# MPS2_SSE_200 register map
Vendor: ARM Ltd.; Series: ARMv8-M Mainline; File version: 1.0
CPU: CM33 r0p0, little endian, MPU, no FPU, 4 interrupt priority bits, 8 SAU regions
Registers are 32-bit, read-write, reset 0x0 unless marked. A register's access mark holds for its fields unless they carry their own. Offsets are from the block's base; [hi:lo] are bit positions; {n}, {i} and the like mark numbered series.

## GPIO0 — General-purpose I/O 0
Base 0x40100000
Same registers: GPIO1 0x40101000, GPIO2 0x40102000, GPIO3 0x40103000, GPIO0_Secure 0x50100000, GPIO1_Secure 0x50101000, GPIO2_Secure 0x50102000, GPIO3_Secure 0x50103000
0x00 DATA
0x04 DATAOUT — Data Output Register
0x10 OUTENSET — Ouptut enable set Register
0x14 OUTENCLR — Ouptut enable clear Register
0x18 ALTFUNCSET — Alternate function set Register
0x1C ALTFUNCCLR — Alternate function clear Register
0x20 INTENSET — Interrupt enable set Register
0x24 INTENCLR — Interrupt enable clear Register
0x28 INTTYPESET — Interrupt type set Register
0x2C INTTYPECLR — Interrupt type clear Register
0x30 INTPOLSET — Polarity-level, edge interrupt configuration set Register
0x34 INTPOLCLR — Polarity-level, edge interrupt configuration clear Register
0x38 INTSTATUS ro — Interrupt Status Register
0x38 INTCLEAR wo write-1-clears (alternate view of INTSTATUS) — Interrupt CLEAR Register

## I2C0
Base 0x40207000
Same registers: I2C1 0x40208000, I2C2 0x4020C000, I2C3 0x4020D000, I2C0_Secure 0x50207000, I2C1_Secure 0x50208000, I2C2_Secure 0x5020C000, I2C3_Secure 0x5020D000
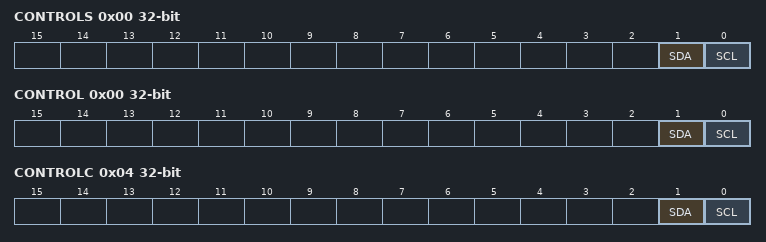
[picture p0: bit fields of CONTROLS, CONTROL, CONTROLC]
0x00 CONTROLS wo — Control Set
  [1] SDA — Serial data line
  [0] SCL — Serial clock line
0x00 CONTROL ro (alternate view of CONTROLS) — Control Status
  [1] SDA — Serial data line
  [0] SCL — Serial clock line
0x04 CONTROLC — Control Clear
  [1] SDA — Serial data line
  [0] SCL — Serial clock line

## WATCHDOG — Non-secure Watchdog Timer
Base 0x40081000
Same registers: S32KWATCHDOG_Secure 0x5002E000, WATCHDOG_Secure 0x50081000
0x00 WDOGLOAD reset 0xFFFFFFFF — Watchdog Load Register
0x04 WDOGVALUE ro reset 0xFFFFFFFF — Watchdog Value Register
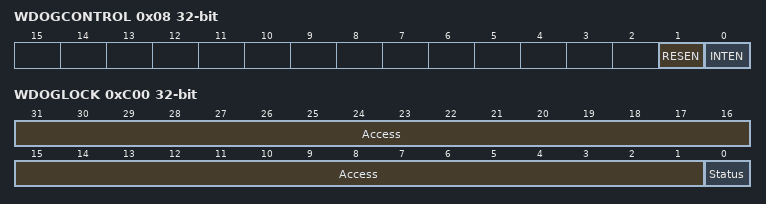
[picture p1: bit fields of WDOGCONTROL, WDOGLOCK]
0x08 WDOGCONTROL — Watchdog Control Register
  [1] RESEN — Enable watchdog reset output
    0=Disable Watchdog reset; 1=Enable Watchdog reset
  [0] INTEN — Enable the interrupt event
    0=Disable Watchdog interrupt; 1=Enable Watchdog interrupt
0x0C WDOGINTCLR wo — Watchdog Interrupt Clear Register
  [0] INT write-1-clears — Interrupt
0x10 WDOGRIS ro — Watchdog Raw Interrupt Status Register
  [0] RIS — Raw watchdog Interrupt
0x14 WDOGMIS ro — Watchdog Mask Interrupt Status Register
  [0] MIS — Masked Watchdog Interrupt
0xC00 WDOGLOCK — Watchdog Lock Register
  [31:1] Access — Enable register writes
  [0] Status — Register write enable status
    0=Enabled (Write access to all other registers is enabled. This is the default.); 1=Disabled (Write access to all other registers is disabled.)

## FPGAIO — FPGA System Control I/O
Base 0x40302000
Same registers: FPGAIO_Secure 0x50302000
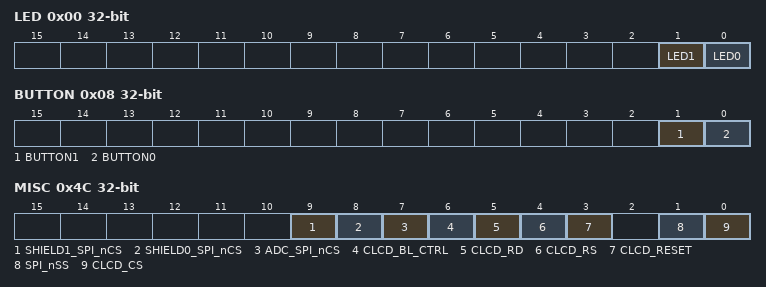
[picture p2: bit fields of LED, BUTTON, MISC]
0x00 LED — LED Connections
  [1] LED1
    0=Off (LED is off); 1=On (LED is on)
  [0] LED0
    0=Off (LED is off); 1=On (LED is on)
0x08 BUTTON — Button Connections
  [1] BUTTON1
    0=Off (BUTTON is off); 1=On (BUTTON is on)
  [0] BUTTON0
    0=Off (BUTTON is off); 1=On (BUTTON is on)
0x10 CLK1HZ ro — 1Hz Up Counter
0x14 CLK100HZ ro — 100Hz Up Counter
0x18 COUNTER — Cycle up counter
0x1C PRESCALER — Reload value for prescaler counter
0x20 PSCNTR — Prescale Counter
0x4C MISC — Misc. Control
  [9] SHIELD1_SPI_nCS, [8] SHIELD0_SPI_nCS, [7] ADC_SPI_nCS, [6] CLCD_BL_CTRL, [5] CLCD_RD, [4] CLCD_RS, [3] CLCD_RESET, [1] SPI_nSS, [0] CLCD_CS

## SCC — Serial Communication Controller
Base 0x40300000
Same registers: SCC_Secure 0x50300000
0x00 CFG_REG0
  [0] REMAP — 1 = REMAP Block RAM to ZBT
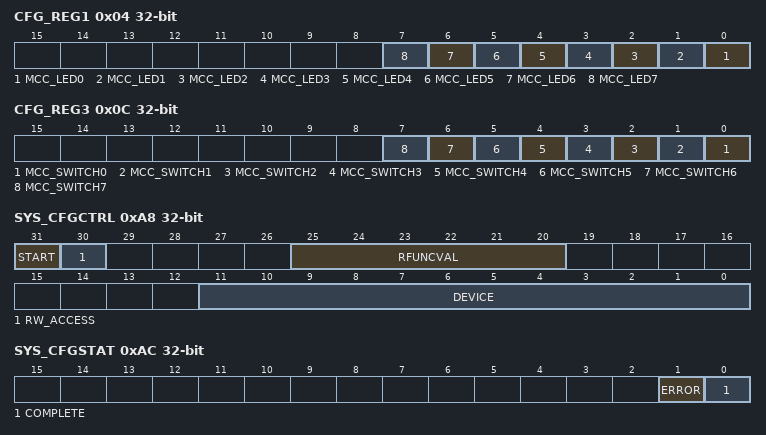
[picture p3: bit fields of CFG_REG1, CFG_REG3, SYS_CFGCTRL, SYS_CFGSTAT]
0x04 CFG_REG1
  [all] fields
    0=Off (LED is off); 1=On (LED is on)
  [n] MCC_LED{n} (n=0..7) — MCC LEDs: 0 = OFF 1 = ON
0x08 CFG_REG2 ro
0x0C CFG_REG3 ro
  [all] fields
    0=Off (Switch is off); 1=On (Switch is on)
  [n] MCC_SWITCH{n} (n=0..7) — MCC SWITCHES: 0 = OFF 1 = ON
0x10 CFG_REG4 ro
  [3:0] BRDREV — Board Revision
0x14 CFG_REG5
  [5] DEBUG — Debug: 0 = Serial Wire Debug 1 = JTAG
0x18 CFG_REG6 ro
0x1C CFG_REG7 ro
0xA0 SYS_CFGDATA_RTN
0xA4 SYS_CFGDATA_OUT
0xA8 SYS_CFGCTRL
  [31] START — Start: generates interrupt on write to this bit
  [30] RW_ACCESS — Read/Write Access
  [25:20] RFUNCVAL — Function Value
  [11:0] DEVICE — Device (value of 0/1/2 for supported clocks
0xAC SYS_CFGSTAT
  [1] ERROR — Error Flag
  [0] COMPLETE — Complete Flag
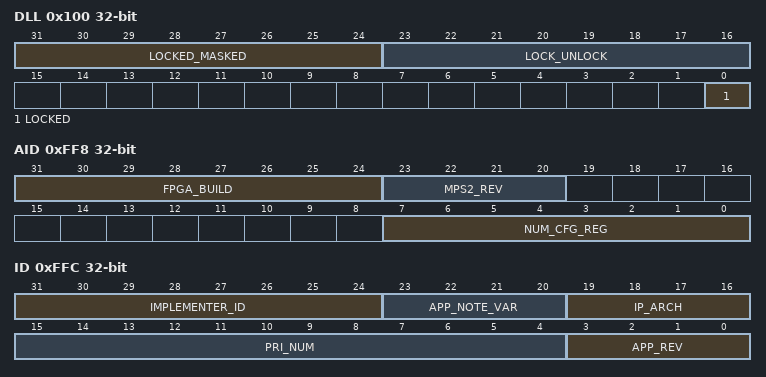
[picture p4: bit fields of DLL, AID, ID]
0x100 DLL — DLL Lock Register
  [31:24] LOCKED_MASKED — Error Flag
  [23:16] LOCK_UNLOCK — Complete Flag
  [0] LOCKED — Complete Flag
0xFF8 AID ro
  [31:24] FPGA_BUILD — FPGA Build Number
  [23:20] MPS2_REV — V2M-MPS2 target Board Revision (A=0,B=1,C=2)
  [7:0] NUM_CFG_REG — Number of SCC configuration register
0xFFC ID ro
  [31:24] IMPLEMENTER_ID — Implementer ID: 0x41 = ARM
  [23:20] APP_NOTE_VAR — Application note IP variant number
  [19:16] IP_ARCH — IP Architecture: 0x4 = AHB
  [15:4] PRI_NUM — Primary Part Number: 521 = AN521
  [3:0] APP_REV — Application note IP revision number
